# R5SS_STC_53500000h register map
Vendor: Texas Instruments
Peripheral module from a debugger description file (folder AM263X).
Registers are 32-bit, read-only, reset 0x0 unless marked. A register's access mark holds for its fields unless they carry their own. Offsets are as the file gives them; lines under a group give offsets from that group; [hi:lo] are bit positions; {n}, {i} and the like mark numbered series; 'fields as' and 'values as' point back to an identical list; <NAME> marks a mode.

## STC
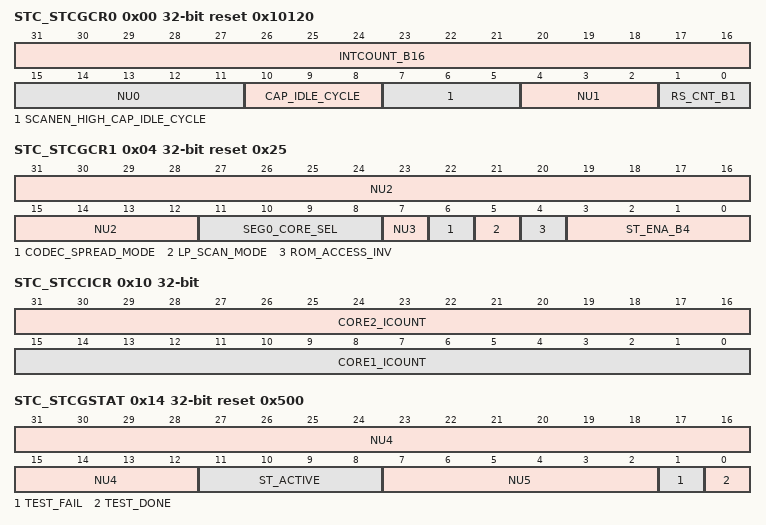
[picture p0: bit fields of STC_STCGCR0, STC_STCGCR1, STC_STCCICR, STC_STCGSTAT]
0x00 STC_STCGCR0 access not given reset 0x10120 — Self test Global control Reg0. *NOT BYTE ACCESSIBLE.
  [31:16] INTCOUNT_B16 rw — Number of intervals of the self test run [RWP - Read, Priviledge Mode Write only]Count of intervals that need to be covered for a specific selftest run.The selftest controller sends out complete indication once it runs all of the intervals programmed in this field.INTCOUNT_B16=0 is an invalid configuration for a selftest.
  [15:11] NU0 ro — Reserved bits
  [10:8] CAP_IDLE_CYCLE rw — Idle cycles before and after capture clock [RWP - Read, Priviledge Mode Write only]Idle Cycles before and after capture clock. This value is used to insert that many idle cycles in the Capture phase. Programmable idle cycles allow implementation flexibility on SCAN_EN signal at chip level based on the size of the UUT and timing requirements.
  [7:5] SCANEN_HIGH_CAP_IDLE_CYCLE rw — Idle cycles before and after capture clock [RWP - Read, Priviledge Mode Write only]. *NOT BYTE ACCESSIBLEIdle Cycles between scan_en going high to func_clk_en generation and scan_en going high to misr_log_en generation. This value is used to insert that many idle cycles in the shift clock [scan_en going high to func_clk_en generation] and misr_log_clk [scan_en going high to misr_log_en generation] generation. Programmable idle cycles allow implementation flexibility on SCAN_EN signal at chip level based on the size of the UUT and timing requirements.
  [4:2] NU1 — Reserved bits (access NU1)
  [1:0] RS_CNT_B1 rw — Restart/Continue or preload [RWP - Read, Priviledge Mode Write only]This bit specifies the selftest controller whether to continue the run from next interval onwards, restart from ROM address 0 or preload from a prescribed interval. This bit gets reset after the completion of selftest run.00 = Continue NSTC run from previous interval01 = Restart NSTC run from ROM address 01X = Start from segment number specified in STC_SEGPLR register
0x04 STC_STCGCR1 access not given reset 0x25 — Self test Global control Reg1.
  [31:12] NU2 — Reserved bits (access NU2)
  [11:8] SEG0_CORE_SEL rw — Selects the Segment0 CORE for self test [RWP - Read, Priviledge Mode Write only]Select the Segment0 CORE for Self -Test0001= Select CORE for selftestOther = CORE not selected.
  [7] NU3 ro — Reserved bits
  [6] CODEC_SPREAD_MODE rw — Codec Spread Mode control signal [RWP - Read, Priviledge Mode Write only]This bit is used to configure the codec in spread / X-OR mode.1 = Spread mode0 = XOR mode
  [5] LP_SCAN_MODE rw — LP scan mode [RWP - Read, Priviledge Mode Write only]This bit is used to decide the scan configuration:1 = Operates in Low Power Scan Mode. 0 = Operates in Normal Scan Mode.
  [4] ROM_ACCESS_INV rw — Rom access inversion mode [RWP - Read, Priviledge Mode Write only]- NOT SUPPORTED
  [3:0] ST_ENA_B4 rw — Self test enable key [RWP - Read, Priviledge Mode Write only]1010= Self test run enabled All values other than1010= Self test run disabled
0x08 STC_STCTPR rw reset 0xFFFFFFFF — Time out counter preload register.
  [31:0] TO_PRELOAD — Self test time out preload [RWP - Read, Priviledge Mode Write only]This register contains the total number of STC clock cycles it will take before a self-test timeout error will be triggered after the initiation of the self-test run. This is a fail safe feature to avoid system hang-up situation on account of any run away self test issues. This register should be loaded with a meaningful count value for this feature to be effective.This register value [preload count value] gets loaded into the self test timeout down counter whenever a self test run is initiated [ST_ENA is enabled]. and gets disabled on completion of a self test run.
0x0C STC_STC_CADDR — Current Address register for CORE1.
  [31:0] ADDR — Current ROM Address for CORE1This register reflects the current ROM address [for micro code load] accessed during selftest for CORE1 in case of segment0 and all the remaining n segments, where n = 1 to 3].
0x10 STC_STCCICR — Current Interval count register.
  [31:16] CORE2_ICOUNT — Specifies the last interval number for CORE2This specifies the Last executed Interval number for CORE2 of Segment0 if self test is being executed for secondary core as well. This field is applicable only for Segment 0.
  [15:0] CORE1_ICOUNT — Specifies the last interval number for CORE1This specifies the Last executed Interval number of a self-test run.
0x14 STC_STCGSTAT reset 0x500 — Global Status Register.
  [31:12] NU4 — Reserved bits
  [11:8] ST_ACTIVE — Indicates whether self test is currently active or not.1010 = Self test is activeOthers = SelfTest is not activeOnce the self-test completes and ST_ENA_B4 key is cleared, this field will reflect the inactive value.
  [7:2] NU5 — Reserved bits
  [1] TEST_FAIL — Test_fail flag [RCP - Read, Clear on Writing in Priviledge Mode]0 = Self test run has not failed1 = SelfTest run has failed. Write Clear.
  [0] TEST_DONE — Test_done_flag [RCP - Read, Clear on Writing in Priviledge Mode]0 = Not completed1 = SelfTest run Completed
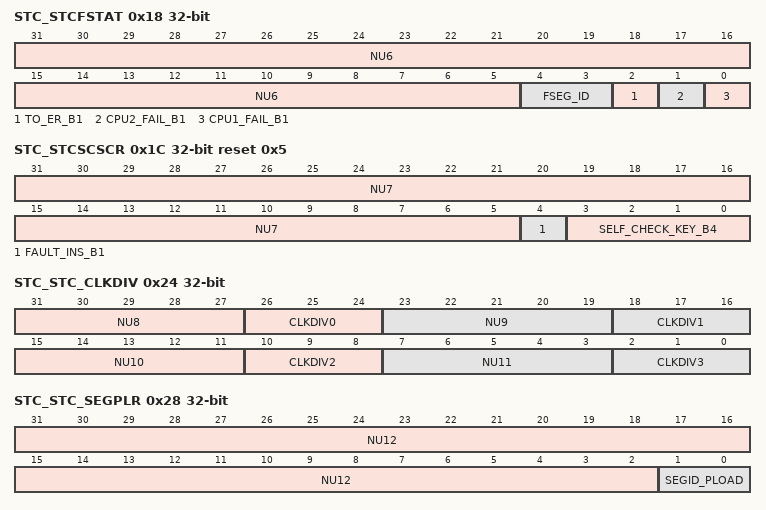
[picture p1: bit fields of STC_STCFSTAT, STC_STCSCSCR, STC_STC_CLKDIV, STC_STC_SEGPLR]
0x18 STC_STCFSTAT — Fail Status Register.
  [31:5] NU6 — Reserved bits
  [4:3] FSEG_ID — Failed Segment ID [RCP - Read, Clear on Writing in Priviledge Mode]This field captures the Segment number for which any of the failures like TO_ER_B1, CPU1_FAIL_B1 and CPU2_FAIL_B1 occur.00 = Failure on Segment 001 = Failure on Segment 110 = Failure on Segment 211 = Failure on Segment 3
  [2] TO_ER_B1 — Indicates whether self test failed because of time out error [RCP - Read, Clear on Writing in Priviledge Mode]0 = No time out error occurred1 = SelfTest run failed due to a timeout error
  [1] CPU2_FAIL_B1 — Indicates whether MISR mismatch happenned in CORE2 when in Segment0 mode [RCP - Read, Clear on Writing in Priviledge Mode]0 = No MISR mismatch for CORE21 = Self test run failed due to MISR mismatch for CORE2
  [0] CPU1_FAIL_B1 — Indicates whether MISR mismatch happenned in CORE1 [RCP - Read, Clear on Writing in Priviledge Mode]Applicable to all segments.0 = No MISR mismatch for CORE11 = Self test run failed due to MISR mismatch for CORE1
0x1C STC_STCSCSCR access per field reset 0x5 — Signature compare Self Check Register.
  [31:5] NU7 ro — Reserved bits
  [4] FAULT_INS_B1 rw — Fault Insertion bit [RWP - Read, Priviledge Mode Write only]0 = No fault insertion.1 = Inserts fault in the logic unedr test which will make signature compare fail. This feature is used as diagnostic check of the STC IP.
  [3:0] SELF_CHECK_KEY_B4 rw — Signature compare logic self check key enable/disable [RWP - Read, Priviledge Mode Write only]1010 = Signature compare logic Self Check is enabledAll values other than1010 = Signature compare logic Self Check is disabled
0x20 STC_STC_CADDR2 — Current Address register for CORE2.
  [31:0] ADDR — Current ROM Address for CORE2This register reflects the current ROM address[for micro code load] accessed during selftest for CORE2 in of case segment0.
0x24 STC_STC_CLKDIV access per field — Clock Divider Register.
  [95-8n:91-8n] NU{n} ro (n=8..11) — Reserved bits
  [26-8n:24-8n] CLKDIV{n} rw (n=0..3) — Clock division for Seg{n} [RWP - Read, Priviledge Mode Write only]*NOT SUPPORTEDX = Division ratio is X+1 for Segment {n}
0x28 STC_STC_SEGPLR access per field — Segment 1st interval Preload Register.
  [31:2] NU12 ro — Reserved bits
  [1:0] SEGID_PLOAD rw — Segment number for which preload is to be started [RWP - Read, Priviledge Mode Write only]This specifies the segment for which the address of its First interval will be pre-loaded into the NSTC ROM address counter. The 1st address of each segment are defined in SEGx_START_ADDR register.The address of the 1st interval of the selected segment is loaded into the NSTC ROM address counter when the RS_CNT_B1 bits of STC_GCR0 are set to 1X00 = Preload the address of the 1st interval of segment 0.01 = Preload the address of the 1st interval of segment 1.10 = Preload the address of the 1st interval of segment 2.11 = Preload the address of the 1st interval of segment 3.
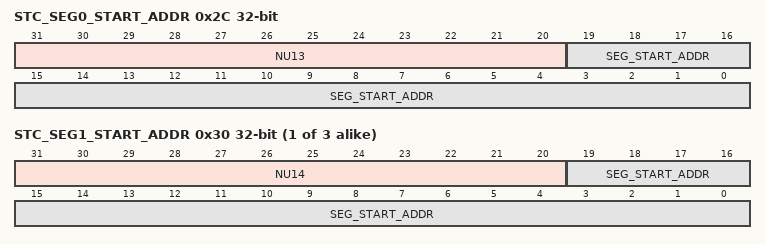
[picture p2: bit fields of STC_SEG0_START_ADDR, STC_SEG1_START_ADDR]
0x2C STC_SEG0_START_ADDR access per field — ROM Start address for Segment0.
  [31:20] NU13 ro — Reserved bits
  [19:0] SEG_START_ADDR rw — Segment 0 Start Address [RWP - Read, Priviledge Mode Write only]This register holds the ROM address for the start of first interval of the segment.When STC_GCR0.RS_CNT_B1 field is set to [1x] PRELOAD option, this register is used to determine the ROM start address for the Segment selected in ST_SEGPLR register.Valid number of bits depends on RTL paramerter ADDR
{0x2C+4i} STC_SEG{i}_START_ADDR access per field (i=1..3) — ROM Start address for Segment{i}.
  [31:20] NU{i+13} ro — Reserved bits
  [19:0] SEG_START_ADDR rw — Segment {i} Start Address [RWP - Read, Priviledge Mode Write only]This register holds the ROM address for the start of first interval of the segment.When STC_GCR0.RS_CNT_B1 field is set to [1x] PRELOAD option, this register is used to determine the ROM start address for the Segment selected in ST_SEGPLR register.Valid number of bits depends on RTL paramerter ADDR.This register is present only when RTL parameter NUM_SEG = {i}.
{0x3C+4i} STC_CORE1_CURMISR_{i} (i=0..27) — Holds the MISR signature for CORE1.
  [31:0] C1MISR{i} — MISR Signature for CORE1This register contains the MISR data of the current interval for CORE1 in the case of segment0 and the remaining Segments 1 to 3. This value will be compared with the GOLDEN MISR value copied from ROM. This register gets reset to its default value with Power on or system reset assertion. The MISR values should be read only after the Self Test is completed.
{0xAC+4i} STC_CORE2_CURMISR_{i} (i=0..27) — Holds the MISR signature for CORE2.
  [31:0] C2MISR{i} — MISR Signature for CORE2This register contains the MISR data from the CORE2 for the current interval. This is applicable to Segment 0 alone. This value will be compared with the GOLDEN MISR value copied from ROM. This register gets reset to its default value with Power on or system reset assertion. The MISR values should be read only after the Self Test is completed.
